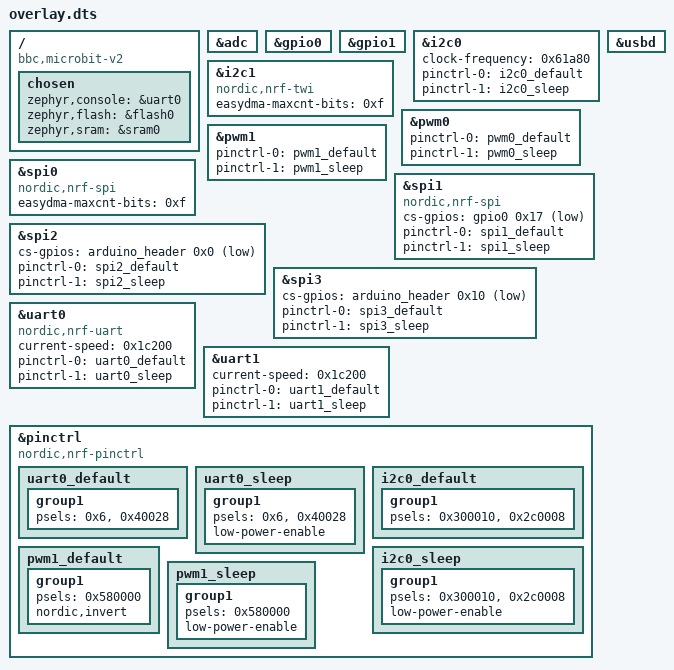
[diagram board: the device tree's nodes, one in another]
/ {
	compatible = "bbc,microbit-v2";
	chosen {
		zephyr,console = &uart0;
		zephyr,flash = &flash0;
		zephyr,sram = &sram0;
	};
};
&adc{
	status = "okay";
};
&gpio0{
	status = "okay";
};
&gpio1{
	status = "okay";
};
&i2c0{
	clock-frequency = < 0x61a80 >;
	status = "okay";
	pinctrl-0 = < &i2c0_default >;
	pinctrl-1 = < &i2c0_sleep >;
	pinctrl-names = "default", "sleep";
};
&i2c1{
	compatible = "nordic,nrf-twi";
	easydma-maxcnt-bits = < 0xf >;
};
&pwm0{
	status = "okay";
	pinctrl-0 = < &pwm0_default >;
	pinctrl-1 = < &pwm0_sleep >;
	pinctrl-names = "default", "sleep";
};
&pwm1{
	status = "okay";
	pinctrl-0 = < &pwm1_default >;
	pinctrl-1 = < &pwm1_sleep >;
	pinctrl-names = "default", "sleep";
};
&spi0{
	compatible = "nordic,nrf-spi";
	easydma-maxcnt-bits = < 0xf >;
};
&spi1{
	compatible = "nordic,nrf-spi";
	status = "okay";
	cs-gpios = < &gpio0 0x17 0x1 >;
	pinctrl-0 = < &spi1_default >;
	pinctrl-1 = < &spi1_sleep >;
	pinctrl-names = "default", "sleep";
};
&spi2{
	status = "okay";
	cs-gpios = < &arduino_header 0x0 0x1 >;
	pinctrl-0 = < &spi2_default >;
	pinctrl-1 = < &spi2_sleep >;
	pinctrl-names = "default", "sleep";
};
&spi3{
	status = "okay";
	cs-gpios = < &arduino_header 0x10 0x1 >;
	pinctrl-0 = < &spi3_default >;
	pinctrl-1 = < &spi3_sleep >;
	pinctrl-names = "default", "sleep";
};
&uart0{
	compatible = "nordic,nrf-uart";
	status = "okay";
	current-speed = < 0x1c200 >;
	pinctrl-0 = < &uart0_default >;
	pinctrl-1 = < &uart0_sleep >;
	pinctrl-names = "default", "sleep";
};
&uart1{
	current-speed = < 0x1c200 >;
	pinctrl-0 = < &uart1_default >;
	pinctrl-1 = < &uart1_sleep >;
	pinctrl-names = "default", "sleep";
};
&usbd{
	status = "okay";
};
&pinctrl{
	compatible = "nordic,nrf-pinctrl";
	uart0_default: uart0_default {
		group1 {
			psels = < 0x6 >, < 0x40028 >;
		};
	};
	uart0_sleep: uart0_sleep {
		group1 {
			psels = < 0x6 >, < 0x40028 >;
			low-power-enable;
		};
	};
	i2c0_default: i2c0_default {
		group1 {
			psels = < 0x300010 >, < 0x2c0008 >;
		};
	};
	i2c0_sleep: i2c0_sleep {
		group1 {
			psels = < 0x300010 >, < 0x2c0008 >;
			low-power-enable;
		};
	};
	pwm1_default: pwm1_default {
		group1 {
			psels = < 0x580000 >;
			nordic,invert;
		};
	};
	pwm1_sleep: pwm1_sleep {
		group1 {
			psels = < 0x580000 >;
			low-power-enable;
		};
	};
};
